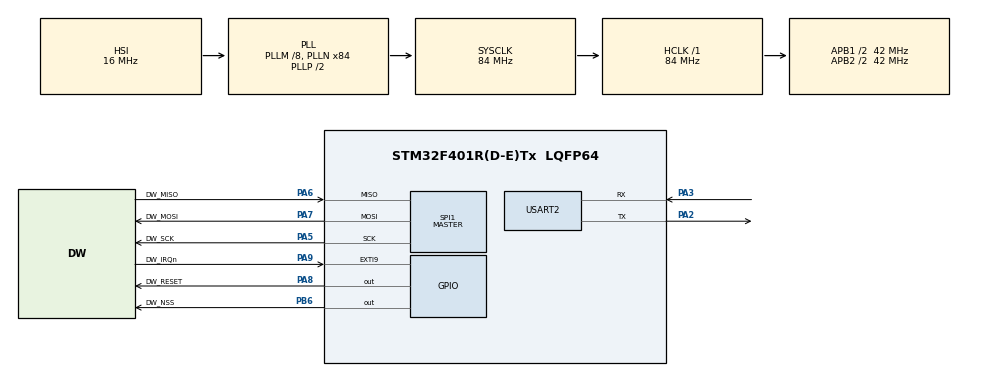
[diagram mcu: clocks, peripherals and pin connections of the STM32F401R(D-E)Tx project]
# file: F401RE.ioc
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Mcu.Family=STM32F4
Mcu.Name=STM32F401R(D-E)Tx
Mcu.Package=LQFP64
NVIC.PriorityGroup=NVIC_PRIORITYGROUP_4
PA13.GPIO_Label=TMS
PA13.Mode=Trace_Asynchronous_SW
PA13.Signal=SYS_JTMS-SWDIO
PA14.GPIO_Label=TCK
PA14.Mode=Trace_Asynchronous_SW
PA14.Signal=SYS_JTCK-SWCLK
PA2.GPIO_PuPd=GPIO_PULLUP
PA2.Mode=Asynchronous
PA2.Signal=USART2_TX
PA3.GPIO_PuPd=GPIO_PULLUP
PA3.Mode=Asynchronous
PA3.Signal=USART2_RX
PA5.GPIO_Label=DW_SCK
PA5.Mode=Full_Duplex_Master
PA5.Signal=SPI1_SCK
PA6.GPIO_Label=DW_MISO
PA6.Mode=Full_Duplex_Master
PA6.Signal=SPI1_MISO
PA7.GPIO_Label=DW_MOSI
PA7.Mode=Full_Duplex_Master
PA7.Signal=SPI1_MOSI
PA8.GPIO_Label=DW_RESET
PA8.GPIO_ModeDefaultOutputPP=GPIO_MODE_OUTPUT_OD
PA8.GPIO_PuPd=GPIO_NOPULL
PA8.GPIO_Speed=GPIO_SPEED_FREQ_MEDIUM
PA8.Signal=GPIO_Output
PA9.GPIO_Label=DW_IRQn
PA9.Signal=GPXTI9
PB3.GPIO_Label=SWO
PB3.Mode=Trace_Asynchronous_SW
PB3.Signal=SYS_JTDO-SWO
PB6.GPIO_Label=DW_NSS
PB6.GPIO_PuPd=GPIO_PULLUP
PB6.GPIO_Speed=GPIO_SPEED_FREQ_MEDIUM
PB6.Signal=GPIO_Output
ProjectManager.HeapSize=0x200
ProjectManager.StackSize=0x400
ProjectManager.TargetToolchain=STM32CubeIDE
RCC.48MHZClocksFreq_Value=24000000
RCC.AHBFreq_Value=84000000
RCC.APB1CLKDivider=RCC_HCLK_DIV2
RCC.APB1Freq_Value=42000000
RCC.APB1TimFreq_Value=84000000
RCC.APB2CLKDivider=RCC_HCLK_DIV2
RCC.APB2Freq_Value=42000000
RCC.APB2TimFreq_Value=84000000
RCC.CortexFreq_Value=84000000
RCC.HCLKFreq_Value=84000000
RCC.HSE_VALUE=8000000
RCC.HSI_VALUE=16000000
RCC.PLLM=8
RCC.PLLN=84
RCC.PLLQ=7
RCC.SYSCLKFreq_VALUE=84000000
RCC.SYSCLKSource=RCC_SYSCLKSOURCE_PLLCLK
RCC.VCOOutputFreq_Value=168000000
SPI1.BaudRatePrescaler=SPI_BAUDRATEPRESCALER_16
SPI1.Direction=SPI_DIRECTION_2LINES
SPI1.Mode=SPI_MODE_MASTER
SPI1.VirtualType=VM_MASTER
USART2.VirtualMode=VM_ASYNC
board=NUCLEO-F401RE

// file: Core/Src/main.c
/* USER CODE BEGIN Header */
/**
  ******************************************************************************
  * @file           : main.c
  * @brief          : Main program body
  ******************************************************************************
  * @attention
  *
  * Copyright (c) 2026 STMicroelectronics.
  * All rights reserved.
  *
  * This software is licensed under terms that can be found in the LICENSE file
  * in the root directory of this software component.
  * If no LICENSE file comes with this software, it is provided AS-IS.
  *
  ******************************************************************************
  */
/* USER CODE END Header */
#include "main.h"

/* USER CODE BEGIN Includes */
#include <port.h>
#include <stm32f4xx_hal.h>
#include <string.h>
/* USER CODE END Includes */

SPI_HandleTypeDef hspi1;

UART_HandleTypeDef huart2;

/* USER CODE BEGIN PV */
SPI_HandleTypeDef   *hcurrent_active_spi=&hspi1;//Is the current active SPI pointer - 1 or 2
host_using_spi_e    host_spi = SPI_1;
uint16_t            pin_io_active_spi=DW_NSS_Pin;//CS IO for SPI. Default SPI1
GPIO_PinState       SPI_CS_state=GPIO_PIN_RESET;//Determine the CS for the IO
/* USER CODE END PV */

void SystemClock_Config(void);
static void MX_GPIO_Init(void);
static void MX_SPI1_Init(void);
static void MX_USART2_UART_Init(void);
/* USER CODE BEGIN PFP */

//int rx_diagnostics(void);
//int rx_test_run(void);
//int rx_twr_test(void);
void uwb_app_run(void); /* 3-CIR capture firmware, see Functions/uwb_app.c */
//int simple_tx(void);
//int tx_twr_test(void);
/*! ------------------------------------------------------------------------------------------------------------------
 * @fn test_run_info()
 *
 * @brief  This gets run info from a test and sends it through virtual COM port.
 *
 * @param data - Message data, this data should be NULL string.
 *
 * output parameters
 *
 * no return value
 */
void print(unsigned char *data)
{
    uint16_t data_length;

    data_length = strlen((const char *)data);

	HAL_UART_Transmit(&huart2, (uint8_t*)data, data_length, 0xFFFF);
	HAL_UART_Transmit(&huart2, (uint8_t *)"\n\r", 2, 0xFFFF);

}

/* USER CODE END PFP */

int main(void)
{

  /* MCU Configuration--------------------------------------------------------*/

  /* Reset of all peripherals, Initializes the Flash interface and the Systick. */
  HAL_Init();

  /* Configure the system clock */
  SystemClock_Config();

  /* Initialize all configured peripherals */
  MX_GPIO_Init();
  MX_SPI1_Init();
  MX_USART2_UART_Init();
  /* USER CODE BEGIN 2 */

  //rx_diagnostics();
  //rx_test_run();
  //rx_twr_test();
  uwb_app_run(); /* never returns; role (tx/rx) is chosen from python/uwb_tool.py */
  //simple_tx();
  //tx_twr_test();
  /* USER CODE END 2 */

  /* Infinite loop */
  while (1)
  {

  }
}

void SystemClock_Config(void)
{
  RCC_OscInitTypeDef RCC_OscInitStruct = {0};
  RCC_ClkInitTypeDef RCC_ClkInitStruct = {0};

  /** Configure the main internal regulator output voltage
  */
  __HAL_RCC_PWR_CLK_ENABLE();
  __HAL_PWR_VOLTAGESCALING_CONFIG(PWR_REGULATOR_VOLTAGE_SCALE2);

  /** Initializes the RCC Oscillators according to the specified parameters
  * in the RCC_OscInitTypeDef structure.
  */
  RCC_OscInitStruct.OscillatorType = RCC_OSCILLATORTYPE_HSI;
  RCC_OscInitStruct.HSIState = RCC_HSI_ON;
  RCC_OscInitStruct.HSICalibrationValue = RCC_HSICALIBRATION_DEFAULT;
  RCC_OscInitStruct.PLL.PLLState = RCC_PLL_ON;
  RCC_OscInitStruct.PLL.PLLSource = RCC_PLLSOURCE_HSI;
  RCC_OscInitStruct.PLL.PLLM = 8;
  RCC_OscInitStruct.PLL.PLLN = 84;
  RCC_OscInitStruct.PLL.PLLP = RCC_PLLP_DIV2;
  RCC_OscInitStruct.PLL.PLLQ = 7;
  if (HAL_RCC_OscConfig(&RCC_OscInitStruct) != HAL_OK)
  {
    Error_Handler();
  }

  /** Initializes the CPU, AHB and APB buses clocks
  */
  RCC_ClkInitStruct.ClockType = RCC_CLOCKTYPE_HCLK|RCC_CLOCKTYPE_SYSCLK
                              |RCC_CLOCKTYPE_PCLK1|RCC_CLOCKTYPE_PCLK2;
  RCC_ClkInitStruct.SYSCLKSource = RCC_SYSCLKSOURCE_PLLCLK;
  RCC_ClkInitStruct.AHBCLKDivider = RCC_SYSCLK_DIV1;
  RCC_ClkInitStruct.APB1CLKDivider = RCC_HCLK_DIV2;
  RCC_ClkInitStruct.APB2CLKDivider = RCC_HCLK_DIV2;

  if (HAL_RCC_ClockConfig(&RCC_ClkInitStruct, FLASH_LATENCY_2) != HAL_OK)
  {
    Error_Handler();
  }
}

static void MX_SPI1_Init(void)
{

  /* SPI1 parameter configuration*/
  hspi1.Instance = SPI1;
  hspi1.Init.Mode = SPI_MODE_MASTER;
  hspi1.Init.Direction = SPI_DIRECTION_2LINES;
  hspi1.Init.DataSize = SPI_DATASIZE_8BIT;
  hspi1.Init.CLKPolarity = SPI_POLARITY_LOW;
  hspi1.Init.CLKPhase = SPI_PHASE_1EDGE;
  hspi1.Init.NSS = SPI_NSS_SOFT;
  hspi1.Init.BaudRatePrescaler = SPI_BAUDRATEPRESCALER_16;
  hspi1.Init.FirstBit = SPI_FIRSTBIT_MSB;
  hspi1.Init.TIMode = SPI_TIMODE_DISABLE;
  hspi1.Init.CRCCalculation = SPI_CRCCALCULATION_DISABLE;
  hspi1.Init.CRCPolynomial = 10;
  if (HAL_SPI_Init(&hspi1) != HAL_OK)
  {
    Error_Handler();
  }

}

static void MX_USART2_UART_Init(void)
{

  huart2.Instance = USART2;
  huart2.Init.BaudRate = 115200;
  huart2.Init.WordLength = UART_WORDLENGTH_8B;
  huart2.Init.StopBits = UART_STOPBITS_1;
  huart2.Init.Parity = UART_PARITY_NONE;
  huart2.Init.Mode = UART_MODE_TX_RX;
  huart2.Init.HwFlowCtl = UART_HWCONTROL_NONE;
  huart2.Init.OverSampling = UART_OVERSAMPLING_16;
  if (HAL_UART_Init(&huart2) != HAL_OK)
  {
    Error_Handler();
  }

}

static void MX_GPIO_Init(void)
{
  GPIO_InitTypeDef GPIO_InitStruct = {0};

  /* GPIO Ports Clock Enable */
  __HAL_RCC_GPIOA_CLK_ENABLE();
  __HAL_RCC_GPIOB_CLK_ENABLE();

  /*Configure GPIO pin Output Level */
  HAL_GPIO_WritePin(DW_RESET_GPIO_Port, DW_RESET_Pin, GPIO_PIN_RESET);

  /*Configure GPIO pin Output Level */
  HAL_GPIO_WritePin(DW_NSS_GPIO_Port, DW_NSS_Pin, GPIO_PIN_RESET);

  /*Configure GPIO pin : DW_RESET_Pin */
  GPIO_InitStruct.Pin = DW_RESET_Pin;
  GPIO_InitStruct.Mode = GPIO_MODE_OUTPUT_OD;
  GPIO_InitStruct.Pull = GPIO_NOPULL;
  GPIO_InitStruct.Speed = GPIO_SPEED_FREQ_MEDIUM;
  HAL_GPIO_Init(DW_RESET_GPIO_Port, &GPIO_InitStruct);

  /*Configure GPIO pin : DW_IRQn_Pin */
  GPIO_InitStruct.Pin = DW_IRQn_Pin;
  GPIO_InitStruct.Mode = GPIO_MODE_IT_RISING;
  GPIO_InitStruct.Pull = GPIO_NOPULL;
  HAL_GPIO_Init(DW_IRQn_GPIO_Port, &GPIO_InitStruct);

  /*Configure GPIO pin : DW_NSS_Pin */
  GPIO_InitStruct.Pin = DW_NSS_Pin;
  GPIO_InitStruct.Mode = GPIO_MODE_OUTPUT_PP;
  GPIO_InitStruct.Pull = GPIO_PULLUP;
  GPIO_InitStruct.Speed = GPIO_SPEED_FREQ_MEDIUM;
  HAL_GPIO_Init(DW_NSS_GPIO_Port, &GPIO_InitStruct);

}

void Error_Handler(void)
{
  __disable_irq();
  while (1)
  {
  }
}
